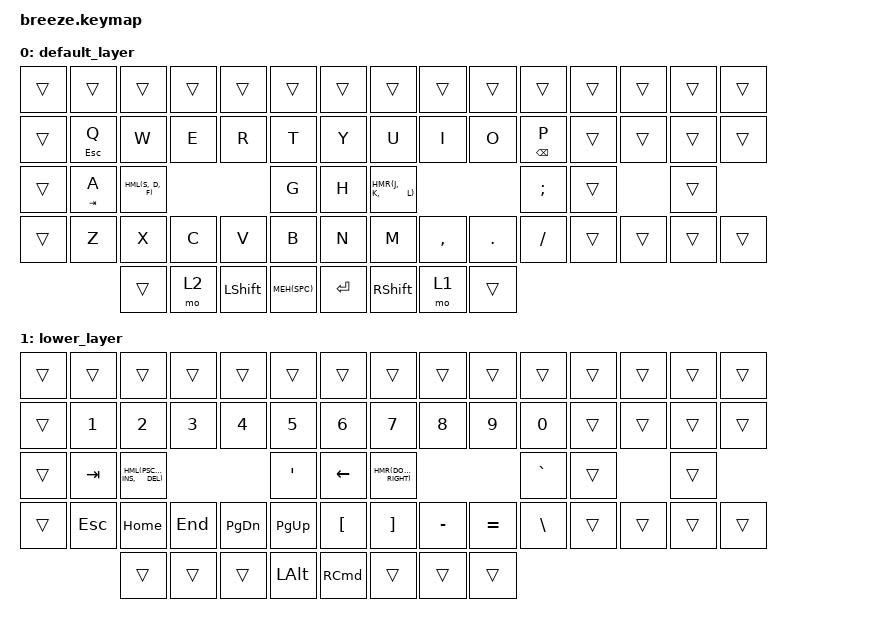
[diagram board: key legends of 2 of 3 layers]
/*
 * Copyright (c) 2022 The ZMK Contributors
 *
 * SPDX-License-Identifier: MIT
 */

#include <behaviors.dtsi>
#include <dt-bindings/zmk/keys.h>
#include <dt-bindings/zmk/bt.h>
#include <dt-bindings/zmk/ext_power.h>



/ {
	behaviors {
		hm: homerow_mods {
			label = "HOMEROW_MODS";
			compatible = "zmk,behavior-hold-tap";
			#binding-cells = <2>;
			tapping-term-ms = <220>;
			quick_tap_ms = <150>;
			global-quick-tap;
			//flavor = "tap-preferred"
			bindings = <&kp>, <&kp>;
		};
	};

#define MEH(k7) &mt LC(LS(LALT)) k7
#define HMR(k1,k2,k3) &hm RCMD k1  &hm RALT k2  &hm RCTRL k3
#define HML(k4,k5,k6) &hm LCTRL k4  &hm LALT k5  &hm LCMD k6
#define BLU(b1) &bt BT_SEL b1

	keymap {
		compatible = "zmk,keymap";

		default_layer {
			bindings = <
//┏━━━━━━━━━┳━━━━━━━━━┳━━━━━━━━━┳━━━━━━━━━┳━━━━━━━━━┳━━━━━━━━━┓    ┏━━━━━━━━━┳━━━━━━━━━┳━━━━━━━━━┳━━━━━━━━━┳━━━━━━━━━━┳━━━━━━━━━┓ ┏━━━━━━━━━┳━━━━━━━━━┳━━━━━━━━━┓
//┃         ┃         ┃         ┃         ┃         ┃         ┃    ┃         ┃         ┃         ┃         ┃         ┃         ┃ ┃         ┃         ┃         ┃
  &trans   &trans    &trans    &trans    &trans     &trans         &trans    &trans    &trans    &trans    &trans    &trans      &trans    &trans    &trans 
//┠─────────╀─────────╀─────────╀─────────╀─────────╀─────────┨    ┠─────────╀─────────╀─────────╀─────────╀─────────╀─────────┨ ┣━━━━━━━━━╋━━━━━━━━━╋━━━━━━━━━┫
//┃         │ Q/ᵉˢᶜ   │  W      │ E       │ R       │ T       ┃    ┃  Y      │  U      │  I      │  O      │ P/BKSP  │         ┃ ┃         ┃         ┃         ┃
  &trans   &hm ESC Q &kp W     &kp E     &kp R      &kp T          &kp Y     &kp U     &kp I     &kp O    &hm BKSP P &trans      &trans    &trans    &trans 
//┠─────────┼─────────┼─────────┼─────────┼─────────┼─────────┨    ┠─────────┼─────────┼─────────┼─────────┼─────────┼─────────┨ ┗━━━━━━━━━╋━━━━━━━━━╋━━━━━━━━━┛
//┃         │ A/tab   │  S/alt  │ D/ctrl  │ F/win   │  G      ┃    ┃ H       │ J/win   │ K/alt   │ L/ctrl  │  ;      │         ┃           ┃         ┃
  &trans   &hm TAB A   HML(S,  D,        F)         &kp G          &kp H     HMR(J,      K,         L)     &kp SEMI  &trans                &trans
//┠─────────┼─────────┼─────────┼─────────┼─────────┼─────────┨    ┠─────────┼─────────┼─────────┼─────────┼─────────┼─────────┨ ┏━━━━━━━━━╋━━━━━━━━━╋━━━━━━━━━┓
//┃         │ Z       │ X       │ C       │ V       │ B       ┃    ┃ N       │ M       │ <,      │ >.      │ ?/      │         ┃ ┃         ┃         ┃         ┃
  &trans   &kp Z     &kp X     &kp C     &kp V      &kp B          &kp N     &kp M     &kp COMMA &kp DOT   &kp FSLH  &trans      &trans    &trans    &trans
//┗━━━━━━━━━┷━━━━━━━━━┷━━━━━━━━━┷━━━━━━━━━┷━━━━━━━━━┷━━━━━━━━━┨    ┣━━━━━━━━━┷━━━━━━━━━┷━━━━━━━━━┷━━━━━━━━━╀━━━━━━━━━┷━━━━━━━━━┛ ┗━━━━━━━━━┻━━━━━━━━━┻━━━━━━━━━┛
//                    ┃        │ Layer 3 │ Shift   │ Space   ┃    ┃ Enter   │ SHIFT   │ Layer 2 │         ┃
                      &trans   &mo 2     &kp LSHIFT MEH(SPC)       &kp RET   &kp RSHIFT &mo 1     &trans 
//                    ┗━━━━━━━━━┷━━━━━━━━━┷━━━━━━━━━┷━━━━━━━━━┛    ┗━━━━━━━━━┷━━━━━━━━━┷━━━━━━━━━┷━━━━━━━━━┛
			>;
		};

		lower_layer {
			bindings = <
//┏━━━━━━━━━┳━━━━━━━━━┳━━━━━━━━━┳━━━━━━━━━┳━━━━━━━━━┳━━━━━━━━━┓    ┏━━━━━━━━━┳━━━━━━━━━┳━━━━━━━━━┳━━━━━━━━━┳━━━━━━━━━━┳━━━━━━━━━┓ ┏━━━━━━━━━┳━━━━━━━━━┳━━━━━━━━━┓
//┃         ┃         ┃         ┃         ┃         ┃         ┃    ┃         ┃         ┃         ┃         ┃         ┃         ┃ ┃         ┃         ┃         ┃
  &trans    &trans    &trans    &trans    &trans    &trans         &trans    &trans    &trans    &trans    &trans    &trans      &trans    &trans    &trans
//┠─────────╀─────────╀─────────╀─────────╀─────────╀─────────┨    ┠─────────╀─────────╀─────────╀─────────╀─────────╀─────────┨ ┣━━━━━━━━━╋━━━━━━━━━╋━━━━━━━━━┫
//┃         │  1!     │  2@     │  3#     │  4$     │  5%     ┃    ┃  6^     │  7&     │  8*     │  9(     │  0)     │         ┃ ┃         ┃         ┃         ┃
  &trans   &kp N1     &kp N2    &kp N3    &kp N4    &kp N5         &kp N6    &kp N7    &kp N8    &kp N9    &kp N0    &trans      &trans    &trans    &trans
//┠─────────┼─────────┼─────────┼─────────┼─────────┼─────────┨    ┠─────────┼─────────┼─────────┼─────────┼─────────┼─────────┨ ┗━━━━━━━━━╋━━━━━━━━━╋━━━━━━━━━┛
//┃         │  Tab    │ PrntScn │ Insert  │ Delete  │  '"     ┃    ┃  L      │  D      │  U      │  R      │  `~     │         ┃           ┃         ┃
  &trans   &kp TAB   HML(PSCRN,  INS,      DEL)    &kp SQT      &kp LEFT  HMR(DOWN,  UP,       RIGHT)  &kp GRAVE   &trans                &trans
//┠─────────┼─────────┼─────────┼─────────┼─────────┼─────────┨    ┠─────────┼─────────┼─────────┼─────────┼─────────┼─────────┨ ┏━━━━━━━━━╋━━━━━━━━━╋━━━━━━━━━┓
//┃         │ Escape  │  Home   │  End    │ PgDn    │  PgUp   ┃    ┃  [{     │  ]}     │  -_     │  =+     │  \|     │         ┃ ┃         ┃         ┃         ┃
  &trans   &kp ESC    &kp HOME   &kp END  &kp PG_DN   &kp PG_UP      &kp LBKT  &kp RBKT  &kp MINUS  &kp EQUAL  &kp BSLH  &trans      &trans    &trans    &trans
//┗━━━━━━━━━┷━━━━━━━━━┷━━━━━━━━━┷━━━━━━━━━┷━━━━━━━━━┷━━━━━━━━━┨    ┣━━━━━━━━━┷━━━━━━━━━┷━━━━━━━━━┷━━━━━━━━━╀━━━━━━━━━┷━━━━━━━━━┛ ┗━━━━━━━━━┻━━━━━━━━━┻━━━━━━━━━┛
//                    ┃        │         │         │         ┃    ┃         │         │        │         ┃
                      &trans   &trans    &trans    &kp LALT         &kp RCMD   &trans     &trans      &trans
//                    ┗━━━━━━━━━┷━━━━━━━━━┷━━━━━━━━━┷━━━━━━━━━┛    ┗━━━━━━━━━┷━━━━━━━━━┷━━━━━━━━━┷━━━━━━━━━┛                       
			>;
		};

		raise_layer {
			bindings = <
//┏━━━━━━━━━┳━━━━━━━━━┳━━━━━━━━━┳━━━━━━━━━┳━━━━━━━━━┳━━━━━━━━━┓    ┏━━━━━━━━━┳━━━━━━━━━┳━━━━━━━━━┳━━━━━━━━━┳━━━━━━━━━━┳━━━━━━━━━┓ ┏━━━━━━━━━┳━━━━━━━━━┳━━━━━━━━━┓
//┃         ┃         ┃         ┃         ┃         ┃         ┃    ┃         ┃         ┃         ┃         ┃         ┃         ┃ ┃         ┃         ┃         ┃
  &trans    &trans    &trans    &trans    &trans    &trans         &trans    &trans    &trans    &trans    &trans    &trans         &trans    &trans    &trans
//┠─────────╀─────────╀─────────╀─────────╀─────────╀─────────┨    ┠─────────╀─────────╀─────────╀─────────╀─────────╀─────────┨ ┣━━━━━━━━━╋━━━━━━━━━╋━━━━━━━━━┫
//┃         │         │         │         │         │         ┃    ┃         │         │         │         │         │         ┃ ┃         ┃         ┃         ┃
  &trans   &kp F1    &kp F2    &kp F3    &kp F4    &kp C_VOL_UP  &kp C_BRI_UP &trans   &trans    &trans    &bt BT_CLR  &trans       &trans    &trans    &trans 
//┠─────────┼─────────┼─────────┼─────────┼─────────┼─────────┨    ┠─────────┼─────────┼─────────┼─────────┼─────────┼─────────┨ ┗━━━━━━━━━╋━━━━━━━━━╋━━━━━━━━━┛
//┃         │         │         │         │         │         ┃    ┃         │         │         │         │         │         ┃           ┃         ┃
  &trans   &kp F5    &kp F6    &kp F7    &kp F8    &kp C_VOL_DN  &kp C_BRI_DN  &kp C_PREV  &kp C_PP  &kp C_NEXT   &trans    &trans            &trans
//┠─────────┼─────────┼─────────┼─────────┼─────────┼─────────┨    ┠─────────┼─────────┼─────────┼─────────┼─────────┼─────────┨ ┏━━━━━━━━━╋━━━━━━━━━╋━━━━━━━━━┓
//┃         │         │         │         │         │         ┃    ┃         │         │         │         │         │         ┃ ┃         ┃         ┃         ┃
  &trans   &kp F9    &kp F10   &kp F11   &kp F12   &kp C_MUTE      BLU(0)    BLU(1)    BLU(2)    BLU(3)    BLU(4)    &trans         &trans    &trans    &trans
//┗━━━━━━━━━┷━━━━━━━━━┷━━━━━━━━━┷━━━━━━━━━┷━━━━━━━━━┷━━━━━━━━━┨    ┣━━━━━━━━━┷━━━━━━━━━┷━━━━━━━━━┷━━━━━━━━━╀━━━━━━━━━┷━━━━━━━━━┛ ┗━━━━━━━━━┻━━━━━━━━━┻━━━━━━━━━┛
//                    ┃        │         │         │         ┃    ┃         │         │        │         ┃
                      &trans    &trans    &trans    &trans         &kp RCMD   &trans     &trans    &trans
//                    ┗━━━━━━━━━┷━━━━━━━━━┷━━━━━━━━━┷━━━━━━━━━┛    ┗━━━━━━━━━┷━━━━━━━━━┷━━━━━━━━━┷━━━━━━━━━┛
			>;
		};
	};
};
